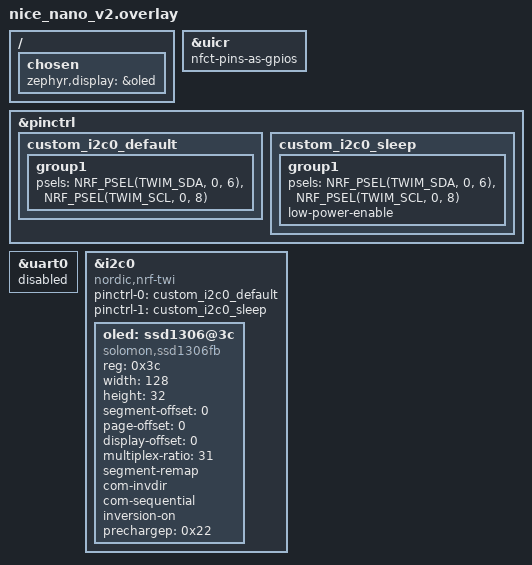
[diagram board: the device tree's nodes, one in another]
/ {
    chosen {
        zephyr,display = &oled;
    };
};

&uicr {
    nfct-pins-as-gpios;
};

&pinctrl {
    custom_i2c0_default: custom_i2c0_default {
        group1 {
            psels = <NRF_PSEL(TWIM_SDA, 0, 6)>,
                    <NRF_PSEL(TWIM_SCL, 0, 8)>;
        };
    };

    custom_i2c0_sleep: custom_i2c0_sleep {
        group1 {
            psels = <NRF_PSEL(TWIM_SDA, 0, 6)>,
                    <NRF_PSEL(TWIM_SCL, 0, 8)>;
            low-power-enable;
        };
    };
};

&uart0 {
    status = "disabled";
};

&i2c0 {
    compatible = "nordic,nrf-twi";
    status = "okay";

    pinctrl-0 = <&custom_i2c0_default>;
    pinctrl-1 = <&custom_i2c0_sleep>;
    pinctrl-names = "default", "sleep";

    oled: ssd1306@3c {
        compatible = "solomon,ssd1306fb";
        reg = <0x3c>;
        width = <128>;
        height = <32>;
        segment-offset = <0>;
        page-offset = <0>;
        display-offset = <0>;
        multiplex-ratio = <31>;
        segment-remap;
        com-invdir;
        com-sequential;
        inversion-on;
        prechargep = <0x22>;
    };
};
